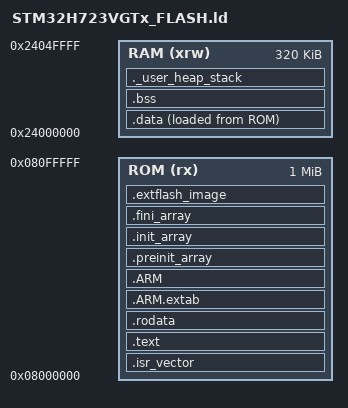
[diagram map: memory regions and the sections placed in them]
ENTRY(Reset_Handler)

_estack = ORIGIN(RAM) + LENGTH(RAM);
_Min_Heap_Size = 0x400;
_Min_Stack_Size = 0x800;

MEMORY
{
  RAM (xrw) : ORIGIN = 0x24000000, LENGTH = 320K
  ROM (rx)  : ORIGIN = 0x08000000, LENGTH = 1024K
}

SECTIONS
{
  .isr_vector :
  {
    . = ALIGN(4);
    KEEP(*(.isr_vector))
    . = ALIGN(4);
  } >ROM

  .text :
  {
    . = ALIGN(4);
    *(.text)
    *(.text*)
    *(.glue_7)
    *(.glue_7t)
    *(.eh_frame)
    KEEP(*(.init))
    KEEP(*(.fini))
    . = ALIGN(4);
    _etext = .;
  } >ROM

  .rodata :
  {
    . = ALIGN(4);
    *(.rodata)
    *(.rodata*)
    . = ALIGN(4);
  } >ROM

  .ARM.extab : { *(.ARM.extab* .gnu.linkonce.armextab.*) } >ROM
  .ARM :
  {
    __exidx_start = .;
    *(.ARM.exidx*)
    __exidx_end = .;
  } >ROM

  .preinit_array :
  {
    PROVIDE_HIDDEN(__preinit_array_start = .);
    KEEP(*(.preinit_array*))
    PROVIDE_HIDDEN(__preinit_array_end = .);
  } >ROM
  .init_array :
  {
    PROVIDE_HIDDEN(__init_array_start = .);
    KEEP(*(SORT(.init_array.*)))
    KEEP(*(.init_array*))
    PROVIDE_HIDDEN(__init_array_end = .);
  } >ROM
  .fini_array :
  {
    PROVIDE_HIDDEN(__fini_array_start = .);
    KEEP(*(SORT(.fini_array.*)))
    KEEP(*(.fini_array*))
    PROVIDE_HIDDEN(__fini_array_end = .);
  } >ROM

  _sidata = LOADADDR(.data);
  .data :
  {
    . = ALIGN(4);
    _sdata = .;
    *(.data)
    *(.data*)
    . = ALIGN(4);
    _edata = .;
  } >RAM AT> ROM

  .bss :
  {
    . = ALIGN(4);
    _sbss = .;
    __bss_start__ = _sbss;
    *(.bss)
    *(.bss*)
    *(COMMON)
    . = ALIGN(4);
    _ebss = .;
    __bss_end__ = _ebss;
  } >RAM

  .extflash_image :
  {
    . = ALIGN(4);
    KEEP(*(.extflash_data*))
    . = ALIGN(4);
  } >ROM

  ._user_heap_stack :
  {
    . = ALIGN(8);
    PROVIDE(end = .);
    PROVIDE(_end = .);
    . = . + _Min_Heap_Size;
    . = . + _Min_Stack_Size;
    . = ALIGN(8);
  } >RAM

  /DISCARD/ :
  {
    *(.comment)
    libm.a:(.data*)
    libm.a:(.bss*)
    libm.a:(COMMON)
  }
  .ARM.attributes 0 : { *(.ARM.attributes) }
}
